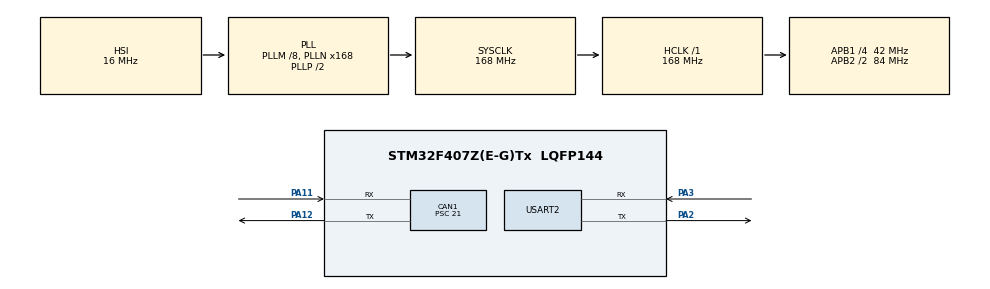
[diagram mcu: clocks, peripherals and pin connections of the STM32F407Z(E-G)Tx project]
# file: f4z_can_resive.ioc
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CAN1.BS1=CAN_BS1_6TQ
CAN1.CalculateBaudRate=250000
CAN1.CalculateTimeBit=4000
CAN1.CalculateTimeQuantum=500.0
CAN1.Prescaler=21
Mcu.Family=STM32F4
Mcu.Name=STM32F407Z(E-G)Tx
Mcu.Package=LQFP144
NVIC.CAN1_RX0_IRQn=true\:0\:0\:false\:false\:true\:true\:true\:true
NVIC.CAN1_RX1_IRQn=true\:0\:0\:false\:false\:true\:true\:true\:true
NVIC.CAN1_SCE_IRQn=true\:0\:0\:false\:false\:true\:true\:true\:true
NVIC.CAN1_TX_IRQn=true\:0\:0\:false\:false\:true\:true\:true\:true
NVIC.PriorityGroup=NVIC_PRIORITYGROUP_4
NVIC.TIM6_DAC_IRQn=true\:0\:0\:false\:false\:true\:true\:true\:true
PA11.Mode=CAN_Activate
PA11.Signal=CAN1_RX
PA12.Mode=CAN_Activate
PA12.Signal=CAN1_TX
PA13.Mode=Serial_Wire
PA13.Signal=SYS_JTMS-SWDIO
PA14.Mode=Serial_Wire
PA14.Signal=SYS_JTCK-SWCLK
PA2.Mode=Asynchronous
PA2.Signal=USART2_TX
PA3.Mode=Asynchronous
PA3.Signal=USART2_RX
PC14-OSC32_IN.Mode=LSE-External-Oscillator
PC14-OSC32_IN.Signal=RCC_OSC32_IN
PC15-OSC32_OUT.Mode=LSE-External-Oscillator
PC15-OSC32_OUT.Signal=RCC_OSC32_OUT
PH0-OSC_IN.Mode=HSE-External-Oscillator
PH0-OSC_IN.Signal=RCC_OSC_IN
PH1-OSC_OUT.Mode=HSE-External-Oscillator
PH1-OSC_OUT.Signal=RCC_OSC_OUT
ProjectManager.HeapSize=0x200
ProjectManager.StackSize=0x400
ProjectManager.TargetToolchain=STM32CubeIDE
RCC.48MHZClocksFreq_Value=84000000
RCC.AHBFreq_Value=168000000
RCC.APB1CLKDivider=RCC_HCLK_DIV4
RCC.APB1Freq_Value=42000000
RCC.APB1TimFreq_Value=84000000
RCC.APB2CLKDivider=RCC_HCLK_DIV2
RCC.APB2Freq_Value=84000000
RCC.APB2TimFreq_Value=168000000
RCC.CortexFreq_Value=168000000
RCC.HCLKFreq_Value=168000000
RCC.HSE_VALUE=8000000
RCC.HSI_VALUE=16000000
RCC.PLLM=8
RCC.PLLN=168
RCC.SYSCLKFreq_VALUE=168000000
RCC.SYSCLKSource=RCC_SYSCLKSOURCE_PLLCLK
RCC.VCOOutputFreq_Value=336000000
TIM6.Period=9999
TIM6.Prescaler=4999
USART2.VirtualMode=VM_ASYNC
VP_TIM6_VS_ClockSourceINT.Mode=Enable_Timer
board=custom

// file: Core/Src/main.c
/* USER CODE BEGIN Header */
/**
  ******************************************************************************
  * @file           : main.c
  * @brief          : Main program body
  ******************************************************************************
  * @attention
  *
  * Copyright (c) 2024 STMicroelectronics.
  * All rights reserved.
  *
  * This software is licensed under terms that can be found in the LICENSE file
  * in the root directory of this software component.
  * If no LICENSE file comes with this software, it is provided AS-IS.
  *
  ******************************************************************************
  */
/* USER CODE END Header */
#include <can.h>
#include "main.h"

CAN_HandleTypeDef hcan1;

TIM_HandleTypeDef htim6;

UART_HandleTypeDef huart2;

void SystemClock_Config(void);
static void MX_GPIO_Init(void);
static void MX_CAN1_Init(void);
static void MX_USART2_UART_Init(void);
static void MX_TIM6_Init(void);

int main(void)
{

  /* MCU Configuration--------------------------------------------------------*/

  /* Reset of all peripherals, Initializes the Flash interface and the Systick. */
  HAL_Init();

  /* Configure the system clock */
  SystemClock_Config();

  /* Initialize all configured peripherals */
  MX_GPIO_Init();
  MX_CAN1_Init();
  MX_USART2_UART_Init();
  MX_TIM6_Init();
  /* USER CODE BEGIN 2 */
 // SM1810C_Init();
  CAN1_Init_Custom();
  /* USER CODE END 2 */

  /* Infinite loop */
  /* USER CODE BEGIN WHILE */
  while (1)
  {
	 // SM1810C_RequestData();
	        // HAL_Delay(500); // Wait for the response (adjust as necessary)
	        // SM1810C_ProcessResponse();
	  //SM1810C_StateMachine();
	       //  HAL_Delay(1000); // Delay between each query
    /* USER CODE END WHILE */

  }
}

void SystemClock_Config(void)
{
  RCC_OscInitTypeDef RCC_OscInitStruct = {0};
  RCC_ClkInitTypeDef RCC_ClkInitStruct = {0};

  /** Configure the main internal regulator output voltage
  */
  __HAL_RCC_PWR_CLK_ENABLE();
  __HAL_PWR_VOLTAGESCALING_CONFIG(PWR_REGULATOR_VOLTAGE_SCALE1);

  /** Initializes the RCC Oscillators according to the specified parameters
  * in the RCC_OscInitTypeDef structure.
  */
  RCC_OscInitStruct.OscillatorType = RCC_OSCILLATORTYPE_HSI;
  RCC_OscInitStruct.HSIState = RCC_HSI_ON;
  RCC_OscInitStruct.HSICalibrationValue = RCC_HSICALIBRATION_DEFAULT;
  RCC_OscInitStruct.PLL.PLLState = RCC_PLL_ON;
  RCC_OscInitStruct.PLL.PLLSource = RCC_PLLSOURCE_HSI;
  RCC_OscInitStruct.PLL.PLLM = 8;
  RCC_OscInitStruct.PLL.PLLN = 168;
  RCC_OscInitStruct.PLL.PLLP = RCC_PLLP_DIV2;
  RCC_OscInitStruct.PLL.PLLQ = 4;
  if (HAL_RCC_OscConfig(&RCC_OscInitStruct) != HAL_OK)
  {
    Error_Handler();
  }

  /** Initializes the CPU, AHB and APB buses clocks
  */
  RCC_ClkInitStruct.ClockType = RCC_CLOCKTYPE_HCLK|RCC_CLOCKTYPE_SYSCLK
                              |RCC_CLOCKTYPE_PCLK1|RCC_CLOCKTYPE_PCLK2;
  RCC_ClkInitStruct.SYSCLKSource = RCC_SYSCLKSOURCE_PLLCLK;
  RCC_ClkInitStruct.AHBCLKDivider = RCC_SYSCLK_DIV1;
  RCC_ClkInitStruct.APB1CLKDivider = RCC_HCLK_DIV4;
  RCC_ClkInitStruct.APB2CLKDivider = RCC_HCLK_DIV2;

  if (HAL_RCC_ClockConfig(&RCC_ClkInitStruct, FLASH_LATENCY_5) != HAL_OK)
  {
    Error_Handler();
  }
}

static void MX_CAN1_Init(void)
{

  hcan1.Instance = CAN1;
  hcan1.Init.Prescaler = 21;
  hcan1.Init.Mode = CAN_MODE_NORMAL;
  hcan1.Init.SyncJumpWidth = CAN_SJW_1TQ;
  hcan1.Init.TimeSeg1 = CAN_BS1_6TQ;
  hcan1.Init.TimeSeg2 = CAN_BS2_1TQ;
  hcan1.Init.TimeTriggeredMode = DISABLE;
  hcan1.Init.AutoBusOff = DISABLE;
  hcan1.Init.AutoWakeUp = DISABLE;
  hcan1.Init.AutoRetransmission = DISABLE;
  hcan1.Init.ReceiveFifoLocked = DISABLE;
  hcan1.Init.TransmitFifoPriority = DISABLE;
  if (HAL_CAN_Init(&hcan1) != HAL_OK)
  {
    Error_Handler();
  }

}

static void MX_TIM6_Init(void)
{

  TIM_MasterConfigTypeDef sMasterConfig = {0};

  htim6.Instance = TIM6;
  htim6.Init.Prescaler = 4999;
  htim6.Init.CounterMode = TIM_COUNTERMODE_UP;
  htim6.Init.Period = 9999;
  htim6.Init.AutoReloadPreload = TIM_AUTORELOAD_PRELOAD_DISABLE;
  if (HAL_TIM_Base_Init(&htim6) != HAL_OK)
  {
    Error_Handler();
  }
  sMasterConfig.MasterOutputTrigger = TIM_TRGO_RESET;
  sMasterConfig.MasterSlaveMode = TIM_MASTERSLAVEMODE_DISABLE;
  if (HAL_TIMEx_MasterConfigSynchronization(&htim6, &sMasterConfig) != HAL_OK)
  {
    Error_Handler();
  }

}

static void MX_USART2_UART_Init(void)
{

  huart2.Instance = USART2;
  huart2.Init.BaudRate = 115200;
  huart2.Init.WordLength = UART_WORDLENGTH_8B;
  huart2.Init.StopBits = UART_STOPBITS_1;
  huart2.Init.Parity = UART_PARITY_NONE;
  huart2.Init.Mode = UART_MODE_TX_RX;
  huart2.Init.HwFlowCtl = UART_HWCONTROL_NONE;
  huart2.Init.OverSampling = UART_OVERSAMPLING_16;
  if (HAL_UART_Init(&huart2) != HAL_OK)
  {
    Error_Handler();
  }

}

static void MX_GPIO_Init(void)
{

  /* GPIO Ports Clock Enable */
  __HAL_RCC_GPIOC_CLK_ENABLE();
  __HAL_RCC_GPIOH_CLK_ENABLE();
  __HAL_RCC_GPIOA_CLK_ENABLE();

}

void Error_Handler(void)
{
  __disable_irq();
  while (1)
  {
  }
}
